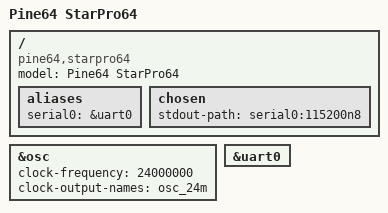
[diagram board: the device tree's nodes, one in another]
// SPDX-License-Identifier: (GPL-2.0 OR MIT)
/*
 * Copyright (c) 2026 Han Gao <gaohan@iscas.ac.cn>
 */

/dts-v1/;

#include "eic7700.dtsi"
#include "eic7700-pinctrl.dtsi"

/ {
	compatible = "pine64,starpro64", "eswin,eic7700";
	model = "Pine64 StarPro64";

	aliases {
		serial0 = &uart0;
	};

	chosen {
		stdout-path = "serial0:115200n8";
	};
};

&osc {
	clock-frequency = <24000000>;
	clock-output-names = "osc_24m";
};

&uart0 {
	status = "okay";
};
